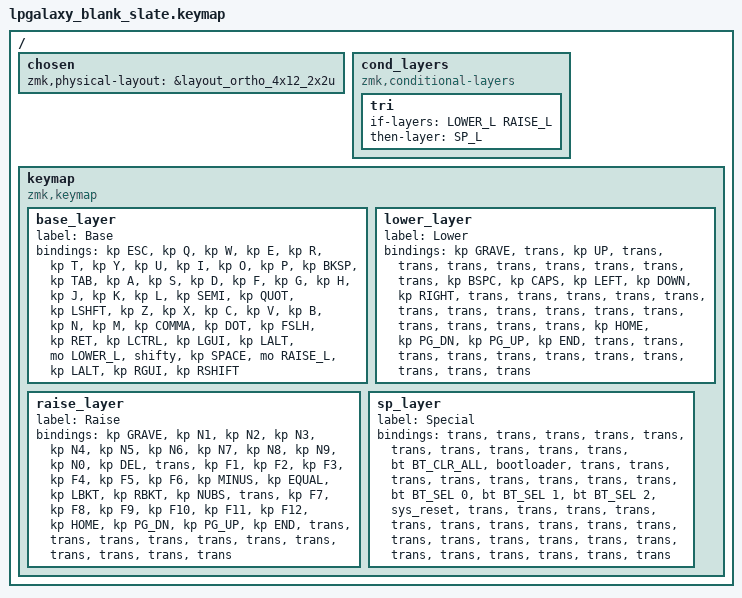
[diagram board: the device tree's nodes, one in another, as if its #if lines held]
/*
 * Copyright (c) 2022 Pete Johanson
 *
 * SPDX-License-Identifier: MIT
 */

#include <behaviors.dtsi>
#include <dt-bindings/zmk/keys.h>
#include <dt-bindings/zmk/bt.h>
#include <dt-bindings/zmk/outputs.h>

#define QWERTY_BASE 1

#define TBLE_ORTHO   1
// #define TBLE_MIT     1
// #define TBLE_DUAL_2U 1

#define LOWER_L 1
#define RAISE_L 2
#define SP_L 3
#define BT(n) BT_SEL n

/ {
    chosen {
       zmk,physical-layout =
#ifdef TBLE_DUAL_2U
                       &layout_ortho_4x12_2x2u;
#elif defined(TBLE_MIT)
                       &layout_ortho_4x12_1x2u;
#else
                       &layout_ortho_4x12_all1u;
#endif
    };

// Conditional layer only when we have less thumb keys
#ifdef TBLE_DUAL_2U
    cond_layers {
        compatible = "zmk,conditional-layers";
	tri {
	    if-layers = <LOWER_L RAISE_L>;
	    then-layer = <SP_L>;
        };
    };
#endif

    keymap {
        compatible = "zmk,keymap";

        base_layer {
            label = "Base";
            bindings = <
#ifdef QWERTY_BASE
 &kp ESC    &kp Q      &kp W      &kp E       &kp R          &kp T          &kp Y            &kp U          &kp I       &kp O      &kp P         &kp BKSP
 &kp TAB    &kp A      &kp S      &kp D       &kp F          &kp G          &kp H            &kp J          &kp K       &kp L      &kp SEMI      &kp QUOT
 &kp LSHFT  &kp Z      &kp X      &kp C       &kp V          &kp B          &kp N            &kp M          &kp COMMA   &kp DOT    &kp FSLH      &kp RET
#else
 &kp ESC    &kp Q      &kp W      &kp F       &kp P          &kp B          &kp J            &kp L          &kp U       &kp Y      &kp QUOT      &kp BKSP
 &kp TAB    &kp A      &kp R      &kp S       &kp T          &kp G          &kp M            &kp N          &kp E       &kp I      &kp O         &kp QUOT
 &kp LSHFT  &kp Z      &kp X      &kp C       &kp D          &kp V          &kp K            &kp H          &kp COMMA   &kp DOT    &kp SEMI      &kp RET
#endif
#ifdef TBLE_DUAL_2U
 &kp LCTRL  &kp LGUI   &kp LALT   &mo LOWER_L     &shifty    &kp SPACE     &mo RAISE_L   &kp LALT    &kp RGUI   &kp RSHIFT
#elif defined(TBLE_MIT)
 &kp LCTRL   &mo SP_L   &kp LGUI  &kp LALT   &mo LOWER_L     &kp SPACE     &mo RAISE_L   &kp LEFT    &kp UP     &kp DOWN     &kp RIGHT
#else
 &kp LCTRL   &kp N1     &kp N2    &kp LALT   &mo LOWER_L     &kp SPACE     &kp SPACE     &mo RAISE_L     &kp N3     &kp N4     &kp N5     &kp RALT
#endif
            >;
        };

        lower_layer {
            label = "Lower";
            bindings = <
&kp GRAVE   &trans     &kp UP     &trans      &trans   &trans   &trans   &trans     &trans      &trans      &trans    &kp BSPC
&kp CAPS    &kp LEFT   &kp DOWN   &kp RIGHT   &trans   &trans   &trans   &trans     &trans      &trans      &trans    &trans
&trans      &trans     &trans     &trans      &trans   &trans   &trans   &kp HOME   &kp PG_DN   &kp PG_UP   &kp END   &trans
#ifdef TBLE_DUAL_2U
&trans      &trans     &trans     &trans           &trans           &trans          &trans      &trans      &trans    &trans
#elif defined(TBLE_MIT)
&trans      &trans     &trans     &trans      &trans        &trans        &trans    &trans      &trans      &trans    &trans
#else
&studio_unlock   &trans   &trans   &kp LGUI   &trans   &trans   &trans   &mo SP_L   &trans   &trans   &trans   &trans
#endif
            >;
        };

        raise_layer {
            label = "Raise";
            bindings = <
&kp GRAVE  &kp N1     &kp N2     &kp N3     &kp N4     &kp N5     &kp N6     &kp N7     &kp N8     &kp N9     &kp N0     &kp DEL
&trans     &kp F1     &kp F2     &kp F3     &kp F4     &kp F5     &kp F6     &kp MINUS  &kp EQUAL  &kp LBKT   &kp RBKT   &kp NUBS
&trans     &kp F7     &kp F8     &kp F9     &kp F10    &kp F11    &kp F12    &kp HOME   &kp PG_DN  &kp PG_UP  &kp END    &trans
#ifdef TBLE_DUAL_2U
&trans    &trans       &trans     &trans            &trans                 &trans            &trans       &trans   &trans   &trans
#elif defined(TBLE_MIT)
&trans    &trans       &trans     &trans     &trans             &trans           &trans      &trans      &trans   &trans   &trans
#else
&studio_unlock   &trans   &trans   &kp LGUI   &mo SP_L   &trans   &trans   &trans   &kp C_NEXT   &kp C_VOL_DN   &kp C_VOL_UP   &kp C_PP
#endif
            >;
        };

        sp_layer {
            label = "Special";
            bindings = <
&trans     &trans   &trans   &trans   &trans   &trans   &trans   &trans   &trans         &trans          &bt BT_CLR_ALL     &bootloader
&trans     &trans   &trans   &trans   &trans   &trans   &trans   &trans   &bt BT_SEL 0   &bt BT_SEL 1    &bt BT_SEL 2       &sys_reset
&trans     &trans   &trans   &trans   &trans   &trans   &trans   &trans   &trans         &trans          &trans             &trans
#ifdef TBLE_DUAL_2U
&trans    &trans       &trans     &trans            &trans                 &trans            &trans       &trans   &trans   &trans
#elif defined(TBLE_MIT)
&trans    &trans       &trans     &trans     &trans             &trans           &trans      &trans      &trans   &trans   &trans
#else
&studio_unlock     &trans     &trans     &trans     &trans     &trans     &trans     &trans     &trans     &trans     &trans     &trans
#endif
            >;
        };


    };
};
